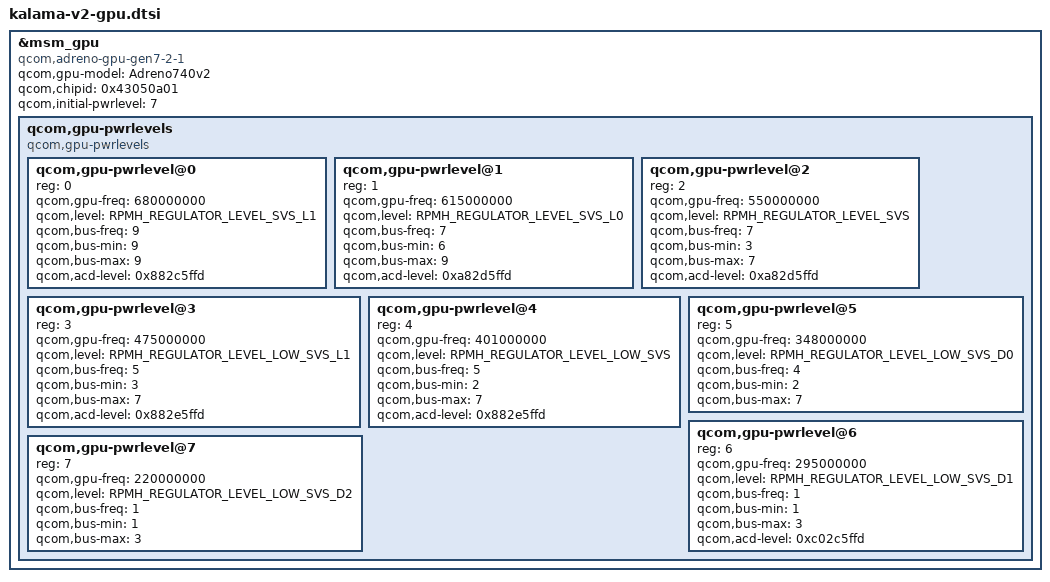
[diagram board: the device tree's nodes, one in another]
#include "kalama-gpu.dtsi"

&msm_gpu {
	compatible = "qcom,adreno-gpu-gen7-2-1", "qcom,kgsl-3d0";

	qcom,gpu-model = "Adreno740v2";

	qcom,chipid = <0x43050a01>;

	qcom,initial-pwrlevel = <7>;

	/* Power levels */
	qcom,gpu-pwrlevels {
		#address-cells = <1>;
		#size-cells = <0>;

		compatible = "qcom,gpu-pwrlevels";

		qcom,gpu-pwrlevel@0 {
			reg = <0>;
			qcom,gpu-freq = <680000000>;
			qcom,level = <RPMH_REGULATOR_LEVEL_SVS_L1>;

			qcom,bus-freq = <9>;
			qcom,bus-min = <9>;
			qcom,bus-max = <9>;

			qcom,acd-level = <0x882c5ffd>;
		};
		qcom,gpu-pwrlevel@1 {
			reg = <1>;
			qcom,gpu-freq = <615000000>;
			qcom,level = <RPMH_REGULATOR_LEVEL_SVS_L0>;

			qcom,bus-freq = <7>;
			qcom,bus-min = <6>;
			qcom,bus-max = <9>;

			qcom,acd-level = <0xa82d5ffd>;
		};
		qcom,gpu-pwrlevel@2 {
			reg = <2>;
			qcom,gpu-freq = <550000000>;
			qcom,level = <RPMH_REGULATOR_LEVEL_SVS>;

			qcom,bus-freq = <7>;
			qcom,bus-min = <3>;
			qcom,bus-max = <7>;

			qcom,acd-level = <0xa82d5ffd>;
		};
		qcom,gpu-pwrlevel@3 {
			reg = <3>;
			qcom,gpu-freq = <475000000>;
			qcom,level = <RPMH_REGULATOR_LEVEL_LOW_SVS_L1>;

			qcom,bus-freq = <5>;
			qcom,bus-min = <3>;
			qcom,bus-max = <7>;

			qcom,acd-level = <0x882e5ffd>;
		};
		qcom,gpu-pwrlevel@4 {
			reg = <4>;
			qcom,gpu-freq = <401000000>;
			qcom,level = <RPMH_REGULATOR_LEVEL_LOW_SVS>;

			qcom,bus-freq = <5>;
			qcom,bus-min = <2>;
			qcom,bus-max = <7>;

			qcom,acd-level = <0x882e5ffd>;
		};
		qcom,gpu-pwrlevel@5 {
			reg = <5>;
			qcom,gpu-freq = <348000000>;
			qcom,level = <RPMH_REGULATOR_LEVEL_LOW_SVS_D0>;

			qcom,bus-freq = <4>;
			qcom,bus-min = <2>;
			qcom,bus-max = <7>;
		};
		qcom,gpu-pwrlevel@6 {
			reg = <6>;
			qcom,gpu-freq = <295000000>;
			qcom,level = <RPMH_REGULATOR_LEVEL_LOW_SVS_D1>;

			qcom,bus-freq = <1>;
			qcom,bus-min = <1>;
			qcom,bus-max = <3>;

			qcom,acd-level = <0xc02c5ffd>;
		};
		qcom,gpu-pwrlevel@7 {
			reg = <7>;
			qcom,gpu-freq = <220000000>;
			qcom,level = <RPMH_REGULATOR_LEVEL_LOW_SVS_D2>;

			qcom,bus-freq = <1>;
			qcom,bus-min = <1>;
			qcom,bus-max = <3>;
		};
	};
};
